# rCSL_emifa_001 register map
Vendor: Texas Instruments
Peripheral module from a debugger description file (folder OMAPL138_C6748).
Registers are 32-bit, access not given, reset 0x0 unless marked. A register's access mark holds for its fields unless they carry their own. Offsets are as the file gives them; lines under a group give offsets from that group; [hi:lo] are bit positions; {n}, {i} and the like mark numbered series; 'fields as' and 'values as' point back to an identical list; <NAME> marks a mode.

## EMIFA — This module provides an interface between TI DSP device and SDRAM & SRAM/NAND devices
0x00 REVID ro reset 0x40000205 — This register contains the revision ID of EMIFA
  [31:0] REV — Revision ID of EMIFA.
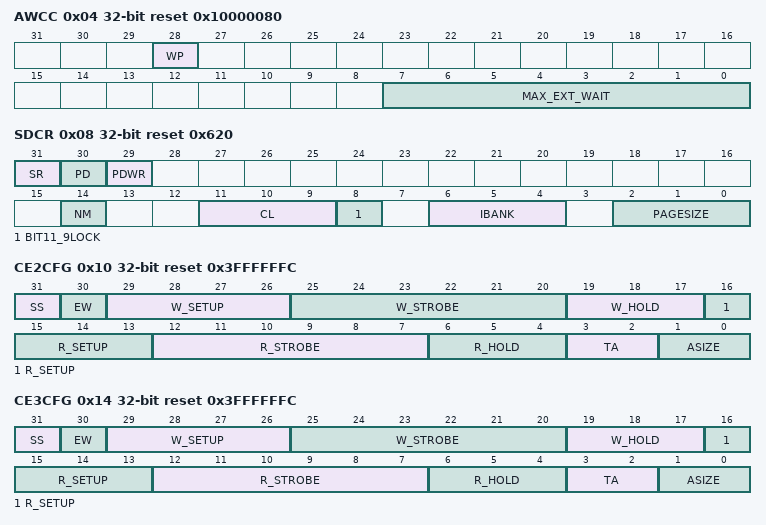
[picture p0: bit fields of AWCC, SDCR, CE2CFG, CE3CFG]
0x04 AWCC reset 0x10000080 — This register is used to configure the parameters for extended wait cycles.Both the polarity of the EMA_WAIT pin and the maximum allowable number of extended wait cycles can be configured.
  [28] WP rw — WAIT polarity bit. This bit defines the polarity of the EM_WAIT pin.
    0=WAIT_ONLOW (0: Insert wait cycles if EM_WAIT is low.); 1=WAIT_ONHIGH (1: Insert wait cycles if EM_WAIT is high.)
  [7:0] MAX_EXT_WAIT rw — Maximum extended wait cycles. The EMIFA will wait for a maximum of (MAX_EXT_WAIT + 1) *16 clock cycles before it stops inserting asynchronous wait cycles and proceeds to the hold period of the access.
0x08 SDCR reset 0x620 — The SDRAM Configuration Register (SDCR) is used to configure various parameters of the SDRAM controller such as the number of internal banks, the internal page size, and the CAS latency to match those of the attached SDRAM device. In addition, this register is used to put the attached SDRAM device into Self-Refresh mode.
  [31] SR rw — Self-Refresh mode bit. This bit controls entering and exiting of the Self-Refresh mode. The field should be written using a byte-write to the upper byte of SDCR to avoid triggering the SDRAM initialization sequence.
    1=SELF_REFRESH (Writing a 1 to this bit will cause connected SDRAM devices and the EMIF to enter the Self-Refresh mode.); 0=NON_SELF_REFRESH (Writing a 0 to this bit will cause connected SDRAM devices and the EMIF to exit the Self-Refresh mode.)
  [30] PD rw — Power Down bit. This bit controls entering and exiting of the Power down mode. The field should be written using a byte-write to the upper byte of SDCR to avoid triggering the SDRAM initialization sequence. If both SR and PD bits are set, the EMIFA will go into Self Refresh.
    1=POWER_DOWN (SDRAM placed in Power down mode.); 0=NON_POWER_DOWN (SDRAM comes out of Power down mode.)
  [29] PDWR rw — Perform refreshes during Power Down. Writing a 1 to this bit will cause the EMIF to exit the power down state and issue an AUTO REFRESH command every time Refresh May level is set.
    1=SET_PDWR (Perform refreshes during powerdown); 0=UNSET_PDWR (No refreshes done during powerdown)
  [14] NM rw — Narrow mode bit. This bit defines whether a 16- or 32-bit-wide SDRAM is connected to the EMIFA. This bit field must be set to 1 if the EMIFA on your device only has 16 data bus pins. Writing to this field triggers the SDRAM initialization sequence.
    0=32BIT (32-bit SDRAM data bus is used.); 1=16BIT (16-bit SDRAM data bus is used.)
  [11:9] CL rw — CAS Latency. This field defines the CAS latency to be used when accessing connected SDRAM devices. A 1 must be simultaniously written to the BIT11_9LOCK bit field of this register in order to write to the CL bit field. Writing to this field triggers the SDRAM initialization sequence.
    2=CAS latency of 2; 3=CAS latency of 3
  [8] BIT11_9LOCK rw — Bits 11 to 9 lock. CL can only be written if BIT11_9LOCK is simultaniously written with a 1. BIT11_9LOCK is always read as 0. Writing to this field triggers the SDRAM initialization sequence.
    0=CL_NO_WRITE (0: CL cannot be written.); 1=CL_WRITE (1: CL can be written.)
  [6:4] IBANK rw — Internal SDRAM Bank size. This field defines number of banks inside the connected SDRAM devices. Writing to this field triggers the SDRAM initialization sequence.
  [2:0] PAGESIZE rw — Page Size. This field defines the internal page size of connected SDRAM devices. Writing to this field triggers the SDRAM initialization sequence.
0x0C SDRCR reset 0x4E2 — This register is used to program SDRAM refresh rate..
  [12:0] RR rw — Refresh Rate. This field is used to define the SDRAM refresh period in terms of EM_CLK cycles. SDRAM refresh rate = EMIF rate / RR where EMIF rate is equal to clk rate.
0x10 CE2CFG rw reset 0x3FFFFFFC — The asynchronous 1 configuration register (corresponding to chip select 2) is used to configure the shaping of the address and control signals during an access to asynchronous memory via CS2. It is also used to program the width of asynchronous interface and to select from various modes of operation. This register can be written prior to any transfer, and any asynchronous transfer following the write will use the new configuration.
  [31] SS — Select Strobe bit. This bit defines whether the asynchronous interface operates in WE Strobe Mode or Select Strobe Mode.
    0=SELSTRB_DISABLE (WE Strobe Mode enabled.); 1=SELSTRB_ENABLE (Select Strobe Mode Enable)
  [30] EW — Extend Wait bit. This bit defines whether extended wait cycles will be enabled. This bit field must be set to 0 if the EMIF on your device does not have an EMA_WAIT pin.
    0=EXT_WAIT_DISABLE (Extended wait cycles disabled.); 1=EXT_WAIT_ENABLE (Extended wait cycles enabled.)
  [29:26] W_SETUP — Write setup width in EMA_CLK cycles, minus one cycle.
  [25:20] W_STROBE — Write strobe width in EMA_CLK cycles, minus one cycle.
  [19:17] W_HOLD — Write hold width in EMA_CLK cycles, minus one cycle.
  [16:13] R_SETUP — Read setup width in EMA_CLK cycles, minus one cycle.
  [12:7] R_STROBE — Read strobe width in EMA_CLK cycles, minus one cycle.
  [6:4] R_HOLD — Read hold width in EMA_CLK cycles, minus one cycle.
  [3:2] TA — Minimum Turn-Around time. This field defines the minimum number of EMA_CLK cycles between reads and writes, minus one cycle. This delay is not incurred by a read followed by a read or a write followed by a write to the same CS space.
  [1:0] ASIZE — Asynchronous Data Bus Width. This field defines the width of the asynchronous device's data bus.
0x14 CE3CFG rw reset 0x3FFFFFFC — The asynchronous 2 configuration register (corresponding to chip select 3) is used to configure the shaping of the address and control signals during an access to asynchronous memory via CS3. It is also used to program the width of asynchronous interface and to select from various modes of operation. This register can be written prior to any transfer, and any asynchronous transfer following the write will use the new configuration.
  [31] SS — Select Strobe bit. This bit defines whether the asynchronous interface operates in WE Strobe Mode or Select Strobe Mode.
    values as CE2CFG.SS
  [30] EW — Extend Wait bit. This bit defines whether extended wait cycles will be enabled. This bit field must be set to 0 if the EMIFA on your device does not have an EMA_WAIT pin.
    values as CE2CFG.EW
  [29:26] W_SETUP — Write setup width in EMA_CLK cycles, minus one cycle.
  [25:20] W_STROBE — Write strobe width in EMA_CLK cycles, minus one cycle.
  [19:17] W_HOLD — Write hold width in EMA_CLK cycles, minus one cycle.
  [16:13] R_SETUP — Read setup width in EMA_CLK cycles, minus one cycle.
  [12:7] R_STROBE — Read strobe width in EMA_CLK cycles, minus one cycle.
  [6:4] R_HOLD — Read hold width in EMA_CLK cycles, minus one cycle.
  [3:2] TA — Minimum Turn-Around time. This field defines the minimum number of EMA_CLK cycles between reads and writes, minus one cycle. This delay is not incurred by a read followed by a read or a write followed by a write to the same CS space.
  [1:0] ASIZE — Asynchronous Data Bus Width. This field defines the width of the asynchronous device's data bus.
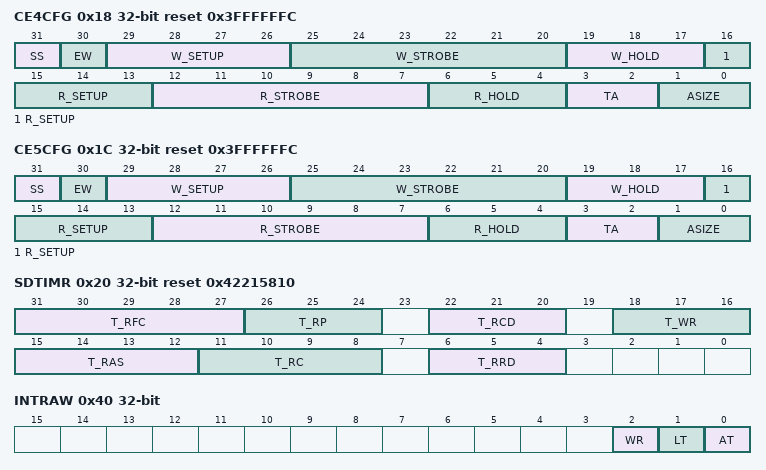
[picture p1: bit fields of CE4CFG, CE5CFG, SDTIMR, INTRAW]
0x18 CE4CFG rw reset 0x3FFFFFFC — The asynchronous 3 configuration register (corresponding to chip select 4) is used to configure the shaping of the address and control signals during an access to asynchronous memory via CS4. It is also used to program the width of asynchronous interface and to select from various modes of operation. This register can be written prior to any transfer, and any asynchronous transfer following the write will use the new configuration.
  fields as CE2CFG
0x1C CE5CFG rw reset 0x3FFFFFFC — The asynchronous 4 configuration register (corresponding to chip select 5) is used to configure the shaping of the address and control signals during an access to asynchronous memory via CS5. It is also used to program the width of asynchronous interface and to select from various modes of operation. This register can be written prior to any transfer, and any asynchronous transfer following the write will use the new configuration.
  fields as CE3CFG
0x20 SDTIMR reset 0x42215810 — The SDRAM Timing Register (SDTIMR) is used to program many of the SDRAM timing parameters. Consult the SDRAM datasheet for information on the appropriate values to program into each field.
  [31:27] T_RFC rw — Specifies the Trfc value of the SDRAM. This defines the minimum number of EMA_CLK cycles from Refresh (REFR) to Refresh (REFR), minus 1: T_RFC = (Trfc/tEMA_CLK) - 1
  [26:24] T_RP rw — Specifies the Trp value of the SDRAM. This defines the minimum number of EMA_CLK cycles from Precharge (PRE) to Activate (ACTV) or Refresh (REFR) command, minus 1: T_RP = (Trp/tEMA_CLK) - 1
  [22:20] T_RCD rw — Specifies the Trcd value of the SDRAM. This defines the minimum number of EMA_CLK cycles from Active (ACTV) to Read (READ) or Write (WRT), minus 1: T_RCD = (Trcd/tEMA_CLK) - 1
  [18:16] T_WR rw — Specifies the Twr value of the SDRAM. This defines the minimum number of EMA_CLK cycles from last Write (WRT) to Precharge (PRE), minus 1: T_WR = (Twr/tEMA_CLK) - 1
  [15:12] T_RAS rw — Specifies the Tras value of the SDRAM. This defines the minimum number of EMA_CLK clock cycles from Activate (ACTV) to Precharge (PRE), minus 1: T_RAS = (Tras/tEMA_CLK) - 1
  [11:8] T_RC rw — Specifies the Trc value of the SDRAM. This defines the minimum number of EMA_CLK clock cycles from Activate (ACTV) to Activate (ACTV), minus 1: T_RC = (Trc/tEMA_CLK) - 1
  [6:4] T_RRD rw — Specifies the Trrd value of the SDRAM. This defines the minimum number of EMA_CLK clock cycles from Activate (ACTV) to Activate (ACTV) for a different bank, minus 1: T_RRD = (Trrd/tEMA_CLK) - 1
0x3C SDSRETR reset 0x9 — The SDRAM Self Refresh Exit Timing Register (SDSRETR) is used to program the amount of time between when the SDRAM exits Self-Refresh mode and when the EMIFA issues another command.
  [4:0] T_XS rw — This field specifies the minimum number of ECLKOUT cycles from Self-Refresh exit to any command, minus one. T_XS = Txsr / tEMA_CLK - 1
0x40 INTRAW — EMIF Interrupt Raw Register
  [2] WR rw — Wait Rise. Set to 1 by hardware to indicate that a rising edge on the EMA_WAIT pin has occurred.
    0=NOT_OCCURRED (Indicates that a rising edge has not occurred on the EM_WAIT pin. Writing a 0 has no effect.); 1=OCCURRED (Indicates that a rising edge has occurred on the EM_WAIT pin.); 1=CLEAR (Writing a 1 will clear this bit and the WR_MASKED bit in the EMIF interrupt mask register (EIMR).)
  [1] LT rw — Line Trap. Set to 1 by hardware to indicate illegal memory access type.
    0=NOT_OCCURRED (Indicates that a line trap has not occurred. Writing a 0 has no effect.); 1=OCCURRED (Indicates that a line trap has occurred.); 1=CLEAR (Writing a 1 will clear this bit and the LT_MASKED bit in the EMIF interrupt mask register (EIMR).)
  [0] AT rw — Asynchronous Timeout. This bit is set to 1 by hardware to indicate that during an extended asynchronous memory access cycle the EMA_WAIT pin did not go inactive within the number of cycles defined by the MAX_EXT_WAIT field in the asynchronous wait cycle configuration register (AWCCR).
    0=NOT_OCCURRED (Indicates that an asynchronous timeout has not occurred. Writing a 0 has no effect.); 1=OCCURRED (Indicates that an asynchronous timeout has occurred.); 1=CLEAR (Writing a 1 will clear this bit and the AT_MASKED bit in the EMIF interrupt mask register (EIMR).)
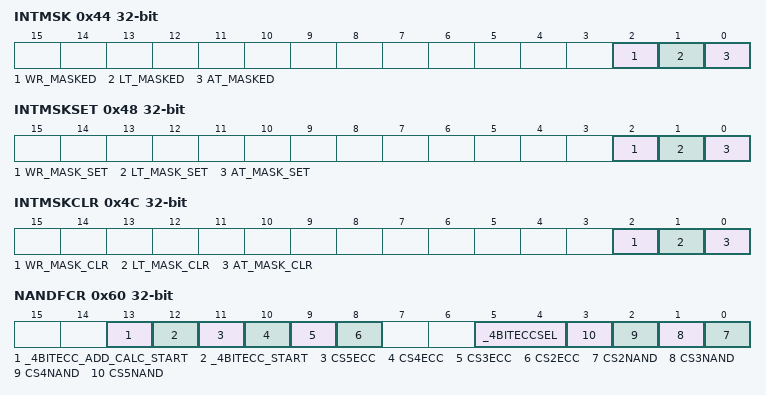
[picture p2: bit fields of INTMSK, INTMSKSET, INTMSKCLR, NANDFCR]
0x44 INTMSK — EMIF Interrupt Mask Register
  [2] WR_MASKED rw — Wait Rise Masked. This bit is set to 1 by hardware to indicate that a rising edge has occurred on the EMA_WAIT pin, provided that the WR_MASK_SET bit is set to 1 in the EMIF interrupt mask set register (INTMSKSET).
    0=NOT_OCCURRED (Indicates that a wait rise interrupt has not been generated. Writing a 0 has no effect.); 1=OCCURRED (Indicates that a wait rise interrupt has been generated.); 1=CLEAR (Writing a 1 will clear this bit and the WR bit in the EMIF interrupt raw register (INTRAW).)
  [1] LT_MASKED rw — Masked Line Trap. Set to 1 by hardware to indicate illegal memory access type, only if the LT_MASK_SET bit in the INTMSKSET is set to 1. Writing a 1 will clear this bit as well as the LT bit in the INTRAW. Writing a 0 has no effect.
    0=NOT_OCCURRED (Indicates that a line trap interrupt has not been generated. Writing a 0 has no effect.); 1=OCCURRED (Indicates that a line trap interrupt has been generated.); 1=CLEAR (Writing a 1 will clear this bit and the LT bit in the EMIF interrupt raw register (INTRAW).)
  [0] AT_MASKED rw — Asynchronous Timeout Masked. This bit is set to 1 by hardware to indicate that during an extended asynchronous memory access cycle the EMA_WAIT pin did not go inactive within the number of cycles defined by the MAX_EXT_WAIT field in the asynchronous wait cycle configuration register (AWCCR), provided that the AT_MASK_SET bit is set to 1 in the EMIF interrupt mask set register (INTMSKSET).
    0=NOT_OCCURRED (Indicates that an asynchronous timeout interrupt has not been generated. Writing a 0 has no effect.); 1=OCCURRED (Indicates that an asynchronous timeout interrupt has been generated.); 1=CLEAR (Writing a 1 will clear this bit and the AT bit in the EMIF interrupt raw register (INTRAW).)
0x48 INTMSKSET — EMIF Interrupt Mask Set Register
  [2] WR_MASK_SET rw — Wait Rise Mask Set. This bit determines whether or not the wait rise Interrupt is enabled. Writing a 1 to this bit sets this bit, sets the WR_MASK_CLR bit in the EMIF interrupt mask clear register (INTMSKCLR), and enables the wait rise interrupt. To clear this bit, a 1 must be written to the WR_MASK_CLR bit in INTMSKCLR.
    0=DISABLED (Indicates that the wait rise interrupt is disabled. Writing a 0 has no effect.); 1=ENABLED (Indicates that the wait rise interrupt is enabled.); 1=SET (Writing a 1 sets this bit and the WR_MASK_CLR bit in the EMIF interrupt mask clear register (EIMCR).)
  [1] LT_MASK_SET rw — Mask set for LT_MASKED bit in the EIMR. Writing a 1 will enable the interrupt, and set this bit as well as the LT_MASK_CLR bit in the INTMSKCLR. The interrupt will not be enabled, and this bit as well as the LT_MASK_CLR bit will not be set if a 1 is written to this bit and the LT_MASK_CLR bit at the same time. Writing a 0 has no effect.
    0=DISABLED (Indicates that the line trap interrupt is disabled. Writing a 0 has no effect.); 1=ENABLED (Indicates that the line trap interrupt is enabled.); 1=SET (Writing a 1 sets this bit and the LT_MASK_CLR bit in the EMIF interrupt mask clear register (EIMCR).)
  [0] AT_MASK_SET rw — Asynchronous Timeout Mask Set. This bit determines whether or not the asynchronous timeout interrupt is enabled. Writing a 1 to this bit sets this bit, sets the AT_MASK_CLR bit in the EMIF interrupt mask clear register (INTMSKCLR), and enables the asynchronous timeout interrupt. To clear this bit, a 1 must be written to the AT_MASK_CLR bit in INTMSKCLR.
    0=DISABLED (Indicates that the asynchronous timeout interrupt is disabled. Writing a 0 has no effect.); 1=ENABLED (Indicates that the asynchronous timeout interrupt is enabled.); 1=SET (Writing a 1 sets this bit and the AT_MASK_CLR bit in the EMIF interrupt mask clear register (EIMCR).)
0x4C INTMSKCLR — EMIF Interrupt Mask Clear Register
  [2] WR_MASK_CLR rw — Wait Rise Mask Clear. This bit determines whether or not the wait rise interrupt is enabled. Writing a 1 to this bit clears this bit, clears the WR_MASK_SET bit in the EMIF interrupt mask set register (INTMSKSET), and disables the wait rise interrupt. To set this bit, a 1 must be written to the WR_MASK_SET bit in EIMSR.
    0=DISABLED (Indicates that the wait rise interrupt is disabled. Writing a 0 has no effect.); 1=ENABLED (Indicates that the wait rise interrupt is enabled.); 1=CLEAR (Writing a 1 clears this bit and the WR_MASK_SET bit in them EMIF interrupt mask set register (INTMSKSET).)
  [1] LT_MASK_CLR rw — Mask clear for LT_MASKED bit in the EIMR. Writing a 1 will disable the interrupt, and clear this bit as well as the LT_MASK_SET bit in the EIMSR. Writing a 0 has no effect.
    0=DISABLED (Indicates that the line trap interrupt is disabled. Writing a 0 has no effect.); 1=ENABLED (Indicates that the line trap interrupt is enabled.); 1=CLEAR (Writing a 1 clears this bit and the LT_MASK_SET bit in them EMIF interrupt mask set register (INTMSKSET).)
  [0] AT_MASK_CLR rw — Asynchronous Timeout Mask Clear. This bit determines whether or not the asynchronous timeout interrupt is enabled. Writing a 1 to this bit clears this bit, clears the AT_MASK_SET bit in the EMIF interrupt mask set register (INTMSKSET), and disables the asynchronous timeout interrupt. To set this bit, a 1 must be written to the AT_MASK_SET bit in EIMSR.
    0=DISABLED (Indicates that the asynchronous timeout interrupt is disabled. Writing a 0 has no effect.); 1=ENABLED (Indicates that the asynchronous timeout interrupt is enabled.); 1=CLEAR (Writing a 1 clears this bit and the AT_MASK_SET bit in the EMIF interrupt mask set register (INTMSKSET).)
0x60 NANDFCR — NAND Flash Control Register
  [13] _4BITECC_ADD_CALC_START rw — NAND Flash 4-bit ECC address and error value calculation Start. Set to 1 to start 4_bit ECC error address and error value calculation on read syndrome. This bit is cleared when any of the NAND Flash Error Address registers or NAND Flash Error Value registers are read.
    1=START (Begins 4-bit ECC Address and Value Calculation)
  [12] _4BITECC_START rw — Nand Flash 4-bit ECC start for the selected chip select. Set to 1 to start 4_bit ECC calculation on data for NAND Flash on chip select selected by bit 4BITECCSEL. This bit is cleared when ay of the NAND Flash 4_bit ECC registers are read.
    1=START (Begins 4-bit ECC Calculation)
  [11] CS5ECC rw — NAND Flash ECC start for chip select 5. Set to 1 to start 1_bit ECC calculation on data for NAND Flash for this chip select. This bit is cleared when CS5 1_bit ECC register is read.
    0=RSVD (Do not start ECC calculation on this chip select); 1=START (Start ECC calculation on this chip select)
  [10] CS4ECC rw — NAND Flash ECC start for chip select 4. Set to 1 to start 1_bit ECC calculation on data for NAND Flash for this chip select. This bit is cleared when CS4 1_bit ECC register is read.
    values as CS5ECC
  [9] CS3ECC rw — NAND Flash 1_bit ECC start for chip select 3. Set to 1 to start 1_bit ECC calculation on data for NAND Flash for this chip select. This bit is cleared when CS3 1_bit ECC register is read.
    values as CS5ECC
  [8] CS2ECC rw — NAND Flash ECC start for chip select 2. Set to 1 to start 1_bit ECC calculation on data for NAND Flash for this chip select. This bit is cleared when CS2 1_bit ECC register is read.
    values as CS5ECC
  [5:4] _4BITECCSEL rw — 4Bit ECC CS selection. This field selects the chip select on which the 4_bit ECC will be calculated.
    {v}=CS{v+2}ECC (CS{v+2} selected for ECC calculation) (v=0..3)
  [n-2] CS{n}NAND rw (n=2..5) — NAND Flash mode for chip select {n}.
    0=NAND_DISABLE (Do not enable NAND Flash on this chip select); 1=NAND_ENABLE (Enable NAND Flash on this chip select)
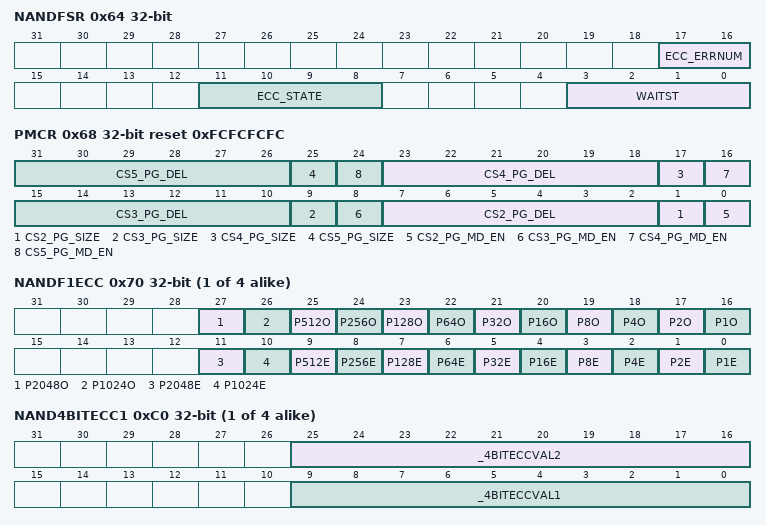
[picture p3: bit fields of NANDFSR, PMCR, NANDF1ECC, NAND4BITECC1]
0x64 NANDFSR — NAND Flash Status Register
  [17:16] ECC_ERRNUM ro — Number of Errors found after the 4-Bit ECC Error Address and Error Value Calculation.
    0=1ERR (1 error found); 1=2ERR (2 errors found); 2=3ERR (3 errors found); 3=4ERR (4 errors found)
  [11:8] ECC_STATE ro — ECC correction state while performing 4-bit ECC Address and Error Value Calculation
  [3:0] WAITST ro — Raw status of the EMA_WAIT input pin. WP0 bit in the asynchronous wait cycle configuration register (AWCCR) has no effect on WAITST.
    1=HIGH; 0=LOW
0x68 PMCR rw reset 0xFCFCFCFC — Page Mode Control Register
  [8n-9:8n-14] CS{n}_PG_DEL (n=2..5) — Page access delay for NOR Flash connected on CS{n}. Number of EMA_CLK cycles required for the page read data to be valid, minus one cycle. This value must not be set to 0.
  [8n-15] CS{n}_PG_SIZE (n=2..5) — Page Size for NOR Flash connected on CS{n}.
    0=4WORDS (Page size is 4 words); 1=8WORDS (Page size is 8 words)
  [8n-16] CS{n}_PG_MD_EN (n=2..5) — Page Mode enable for NOR Flash connected on CS{n}.
    0=DISABLE (Page mode disabled for this chip select); 1=ENABLE (Page mode enabled for this chip select)
{0x6C+4i} NANDF{i}ECC (i=1..4) — NAND Flash {i} ECC Register
  [27] P2048O ro — 1-Bit ECC code calculated while reading/writing NAND Flash.
  [26] P1024O ro — 1-Bit ECC code calculated while reading/writing NAND Flash.
  [25] P512O ro — 1-Bit ECC code calculated while reading/writing NAND Flash.
  [24] P256O ro — 1-Bit ECC code calculated while reading/writing NAND Flash.
  [23] P128O ro — 1-Bit ECC code calculated while reading/writing NAND Flash.
  [22] P64O ro — 1-Bit ECC code calculated while reading/writing NAND Flash.
  [21] P32O ro — 1-Bit ECC code calculated while reading/writing NAND Flash.
  [20] P16O ro — 1-Bit ECC code calculated while reading/writing NAND Flash.
  [19] P8O ro — 1-Bit ECC code calculated while reading/writing NAND Flash.
  [18] P4O ro — 1-Bit ECC code calculated while reading/writing NAND Flash.
  [17] P2O ro — 1-Bit ECC code calculated while reading/writing NAND Flash.
  [16] P1O ro — 1-Bit ECC code calculated while reading/writing NAND Flash.
  [11] P2048E ro — 1-Bit ECC code calculated while reading/writing NAND Flash.
  [10] P1024E ro — 1-Bit ECC code calculated while reading/writing NAND Flash.
  [9] P512E ro — 1-Bit ECC code calculated while reading/writing NAND Flash.
  [8] P256E ro — 1-Bit ECC code calculated while reading/writing NAND Flash.
  [7] P128E ro — 1-Bit ECC code calculated while reading/writing NAND Flash.
  [6] P64E ro — 1-Bit ECC code calculated while reading/writing NAND Flash.
  [5] P32E ro — 1-Bit ECC code calculated while reading/writing NAND Flash.
  [4] P16E ro — 1-Bit ECC code calculated while reading/writing NAND Flash.
  [3] P8E ro — 1-Bit ECC code calculated while reading/writing NAND Flash.
  [2] P4E ro — 1-Bit ECC code calculated while reading/writing NAND Flash.
  [1] P2E ro — 1-Bit ECC code calculated while reading/writing NAND Flash.
  [0] P1E ro — 1-Bit ECC code calculated while reading/writing NAND Flash.
0xBC NAND4BITECCLOAD — NAND Flash 4-bit ECC LOAD Register
  [9:0] _4BITECCLOAD rw — 4-bit ECC load. This register is used to load the ECC values when performing the Syndrome calculation during reads
{0xBC+4i} NAND4BITECC{i} (i=1..4) — NAND Flash 4-bit ECC Register {i}
  [25:16] _4BITECCVAL{2i} ro — Calculated 4-bit ECC or Syndrom Value {2i}
  [9:0] _4BITECCVAL{2i-1} ro — Calculated 4-bit ECC or Syndrom Value {2i-1}
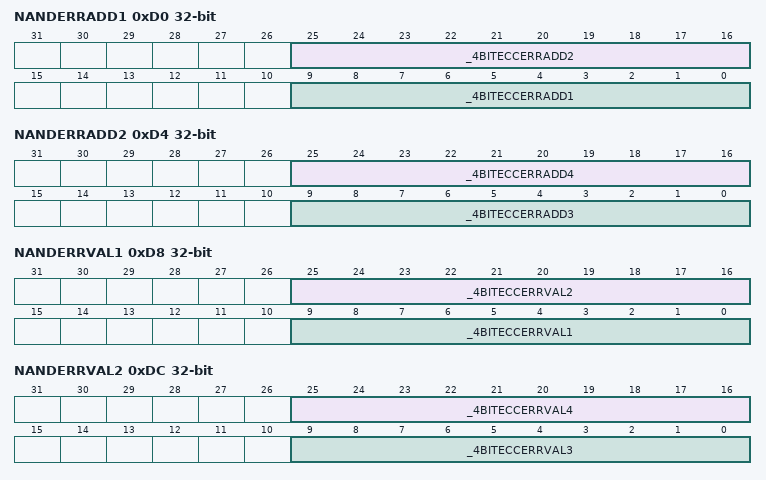
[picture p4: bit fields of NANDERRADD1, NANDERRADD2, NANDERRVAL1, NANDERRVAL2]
0xD0 NANDERRADD1 — NAND Flash 4-bit ECC Error Address Register 1
  [25:16] _4BITECCERRADD2 ro — Calculated 4-bit ECC Error Address 2
  [9:0] _4BITECCERRADD1 ro — Calculated 4-bit ECC Error Address 1
0xD4 NANDERRADD2 — NAND Flash 4-bit ECC Error Address Register 2
  [25:16] _4BITECCERRADD4 ro — Calculated 4-bit ECC Error Address 4
  [9:0] _4BITECCERRADD3 ro — Calculated 4-bit ECC Error Address 3
0xD8 NANDERRVAL1 — NAND Flash 4-bit ECC Error Value Register 1
  [25:16] _4BITECCERRVAL2 ro — Calculated 4-bit ECC Error Value 2
  [9:0] _4BITECCERRVAL1 ro — Calculated 4-bit ECC Error Value 1
0xDC NANDERRVAL2 — NAND Flash 4-bit ECC Error Value Register 2
  [25:16] _4BITECCERRVAL4 ro — Calculated 4-bit ECC Error Value 4
  [9:0] _4BITECCERRVAL3 ro — Calculated 4-bit ECC Error Value 3
